# PIC32MK1024MCF100 register map
Vendor: Microchip
Registers are 32-bit, read-write, reset 0x0 unless marked. A register's access mark holds for its fields unless they carry their own. Addresses are absolute, and some are shared; only a register's first bit layout is shown; [hi:lo] are bit positions.

## ICAP10
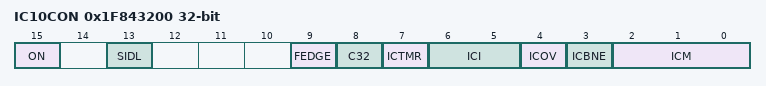
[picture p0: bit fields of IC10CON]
0x1F843200 IC10CON
  [15] ON, [13] SIDL, [9] FEDGE, [8] C32, [7] ICTMR, [6:5] ICI, [4] ICOV ro, [3] ICBNE ro, [2:0] ICM
0x1F843210 IC10BUF ro reset not defined — (power-on value xxxxxxxxxxxxxxxxxxxxxxxxxxxxxxxx)

## ICAP11
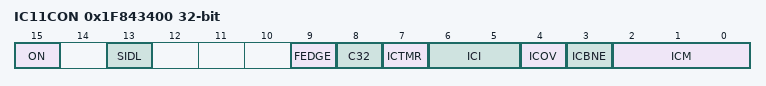
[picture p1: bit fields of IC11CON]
0x1F843400 IC11CON
  [15] ON, [13] SIDL, [9] FEDGE, [8] C32, [7] ICTMR, [6:5] ICI, [4] ICOV ro, [3] ICBNE ro, [2:0] ICM
0x1F843410 IC11BUF ro reset not defined — (power-on value xxxxxxxxxxxxxxxxxxxxxxxxxxxxxxxx)

## ICAP12
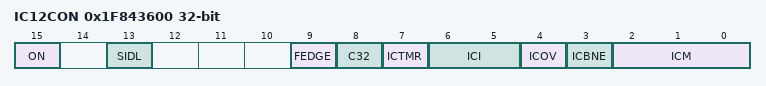
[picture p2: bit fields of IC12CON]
0x1F843600 IC12CON
  [15] ON, [13] SIDL, [9] FEDGE, [8] C32, [7] ICTMR, [6:5] ICI, [4] ICOV ro, [3] ICBNE ro, [2:0] ICM
0x1F843610 IC12BUF ro reset not defined — (power-on value xxxxxxxxxxxxxxxxxxxxxxxxxxxxxxxx)

## ICAP13
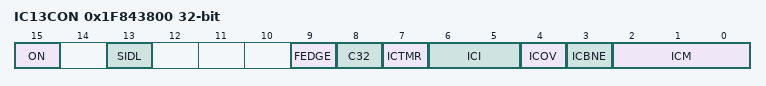
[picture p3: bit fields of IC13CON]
0x1F843800 IC13CON
  [15] ON, [13] SIDL, [9] FEDGE, [8] C32, [7] ICTMR, [6:5] ICI, [4] ICOV ro, [3] ICBNE ro, [2:0] ICM
0x1F843810 IC13BUF ro reset not defined — (power-on value xxxxxxxxxxxxxxxxxxxxxxxxxxxxxxxx)

## ICAP14
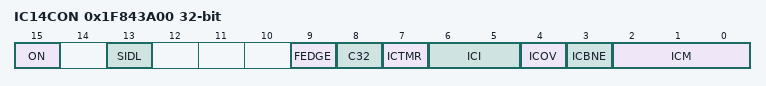
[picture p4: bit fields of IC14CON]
0x1F843A00 IC14CON
  [15] ON, [13] SIDL, [9] FEDGE, [8] C32, [7] ICTMR, [6:5] ICI, [4] ICOV ro, [3] ICBNE ro, [2:0] ICM
0x1F843A10 IC14BUF ro reset not defined — (power-on value xxxxxxxxxxxxxxxxxxxxxxxxxxxxxxxx)

## ICAP15
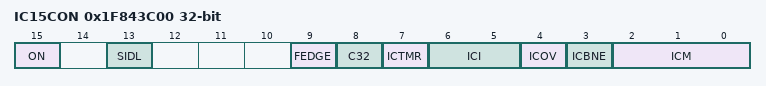
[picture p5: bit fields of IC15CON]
0x1F843C00 IC15CON
  [15] ON, [13] SIDL, [9] FEDGE, [8] C32, [7] ICTMR, [6:5] ICI, [4] ICOV ro, [3] ICBNE ro, [2:0] ICM
0x1F843C10 IC15BUF ro reset not defined — (power-on value xxxxxxxxxxxxxxxxxxxxxxxxxxxxxxxx)

## ICAP16
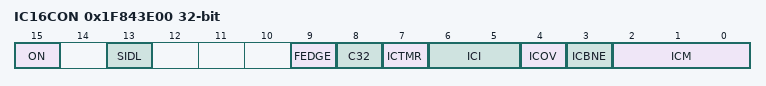
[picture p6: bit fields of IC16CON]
0x1F843E00 IC16CON
  [15] ON, [13] SIDL, [9] FEDGE, [8] C32, [7] ICTMR, [6:5] ICI, [4] ICOV ro, [3] ICBNE ro, [2:0] ICM
0x1F843E10 IC16BUF ro reset not defined — (power-on value xxxxxxxxxxxxxxxxxxxxxxxxxxxxxxxx)

## OCMP10
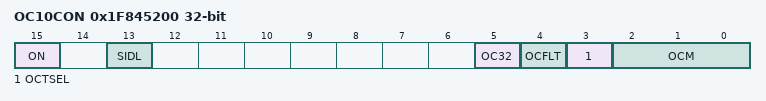
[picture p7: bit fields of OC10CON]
0x1F845200 OC10CON
  [15] ON, [13] SIDL, [5] OC32, [4] OCFLT ro, [3] OCTSEL, [2:0] OCM
0x1F845210 OC10R reset not defined — (power-on value xxxxxxxxxxxxxxxxxxxxxxxxxxxxxxxx)
0x1F845220 OC10RS reset not defined — (power-on value xxxxxxxxxxxxxxxxxxxxxxxxxxxxxxxx)

## OCMP11
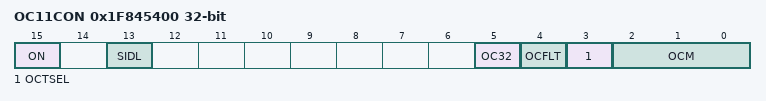
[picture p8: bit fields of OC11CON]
0x1F845400 OC11CON
  [15] ON, [13] SIDL, [5] OC32, [4] OCFLT ro, [3] OCTSEL, [2:0] OCM
0x1F845410 OC11R reset not defined — (power-on value xxxxxxxxxxxxxxxxxxxxxxxxxxxxxxxx)
0x1F845420 OC11RS reset not defined — (power-on value xxxxxxxxxxxxxxxxxxxxxxxxxxxxxxxx)

## OCMP12
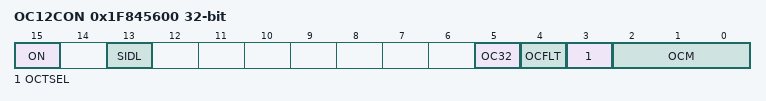
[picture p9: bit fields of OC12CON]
0x1F845600 OC12CON
  [15] ON, [13] SIDL, [5] OC32, [4] OCFLT ro, [3] OCTSEL, [2:0] OCM
0x1F845610 OC12R reset not defined — (power-on value xxxxxxxxxxxxxxxxxxxxxxxxxxxxxxxx)
0x1F845620 OC12RS reset not defined — (power-on value xxxxxxxxxxxxxxxxxxxxxxxxxxxxxxxx)

## OCMP13
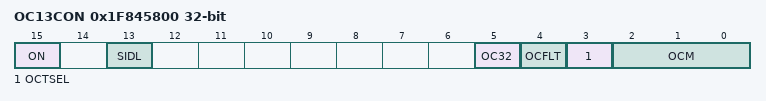
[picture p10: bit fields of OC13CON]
0x1F845800 OC13CON
  [15] ON, [13] SIDL, [5] OC32, [4] OCFLT ro, [3] OCTSEL, [2:0] OCM
0x1F845810 OC13R reset not defined — (power-on value xxxxxxxxxxxxxxxxxxxxxxxxxxxxxxxx)
0x1F845820 OC13RS reset not defined — (power-on value xxxxxxxxxxxxxxxxxxxxxxxxxxxxxxxx)

## OCMP14
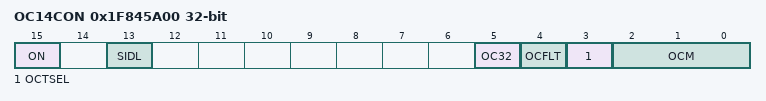
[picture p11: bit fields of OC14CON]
0x1F845A00 OC14CON
  [15] ON, [13] SIDL, [5] OC32, [4] OCFLT ro, [3] OCTSEL, [2:0] OCM
0x1F845A10 OC14R reset not defined — (power-on value xxxxxxxxxxxxxxxxxxxxxxxxxxxxxxxx)
0x1F845A20 OC14RS reset not defined — (power-on value xxxxxxxxxxxxxxxxxxxxxxxxxxxxxxxx)

## OCMP15
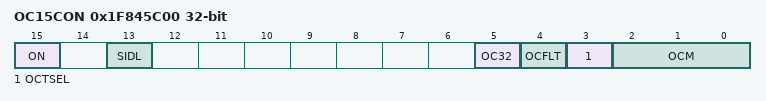
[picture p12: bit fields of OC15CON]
0x1F845C00 OC15CON
  [15] ON, [13] SIDL, [5] OC32, [4] OCFLT ro, [3] OCTSEL, [2:0] OCM
0x1F845C10 OC15R reset not defined — (power-on value xxxxxxxxxxxxxxxxxxxxxxxxxxxxxxxx)
0x1F845C20 OC15RS reset not defined — (power-on value xxxxxxxxxxxxxxxxxxxxxxxxxxxxxxxx)

## OCMP16
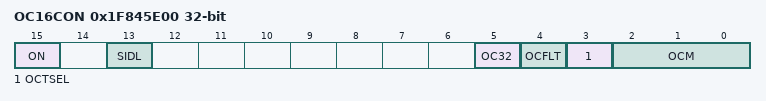
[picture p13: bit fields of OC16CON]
0x1F845E00 OC16CON
  [15] ON, [13] SIDL, [5] OC32, [4] OCFLT ro, [3] OCTSEL, [2:0] OCM
0x1F845E10 OC16R reset not defined — (power-on value xxxxxxxxxxxxxxxxxxxxxxxxxxxxxxxx)
0x1F845E20 OC16RS reset not defined — (power-on value xxxxxxxxxxxxxxxxxxxxxxxxxxxxxxxx)
